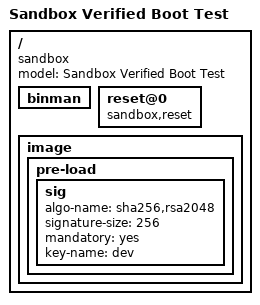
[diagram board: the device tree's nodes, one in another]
// SPDX-License-Identifier: GPL-2.0+

/dts-v1/;

/ {
	model = "Sandbox Verified Boot Test";
	compatible = "sandbox";

	binman {
	};

	reset@0 {
		compatible = "sandbox,reset";
	};

	image {
		pre-load {
			sig {
				algo-name = "sha256,rsa2048";
				signature-size = <256>;
				mandatory = "yes";

				key-name = "dev";
			};
		};
	};
};
